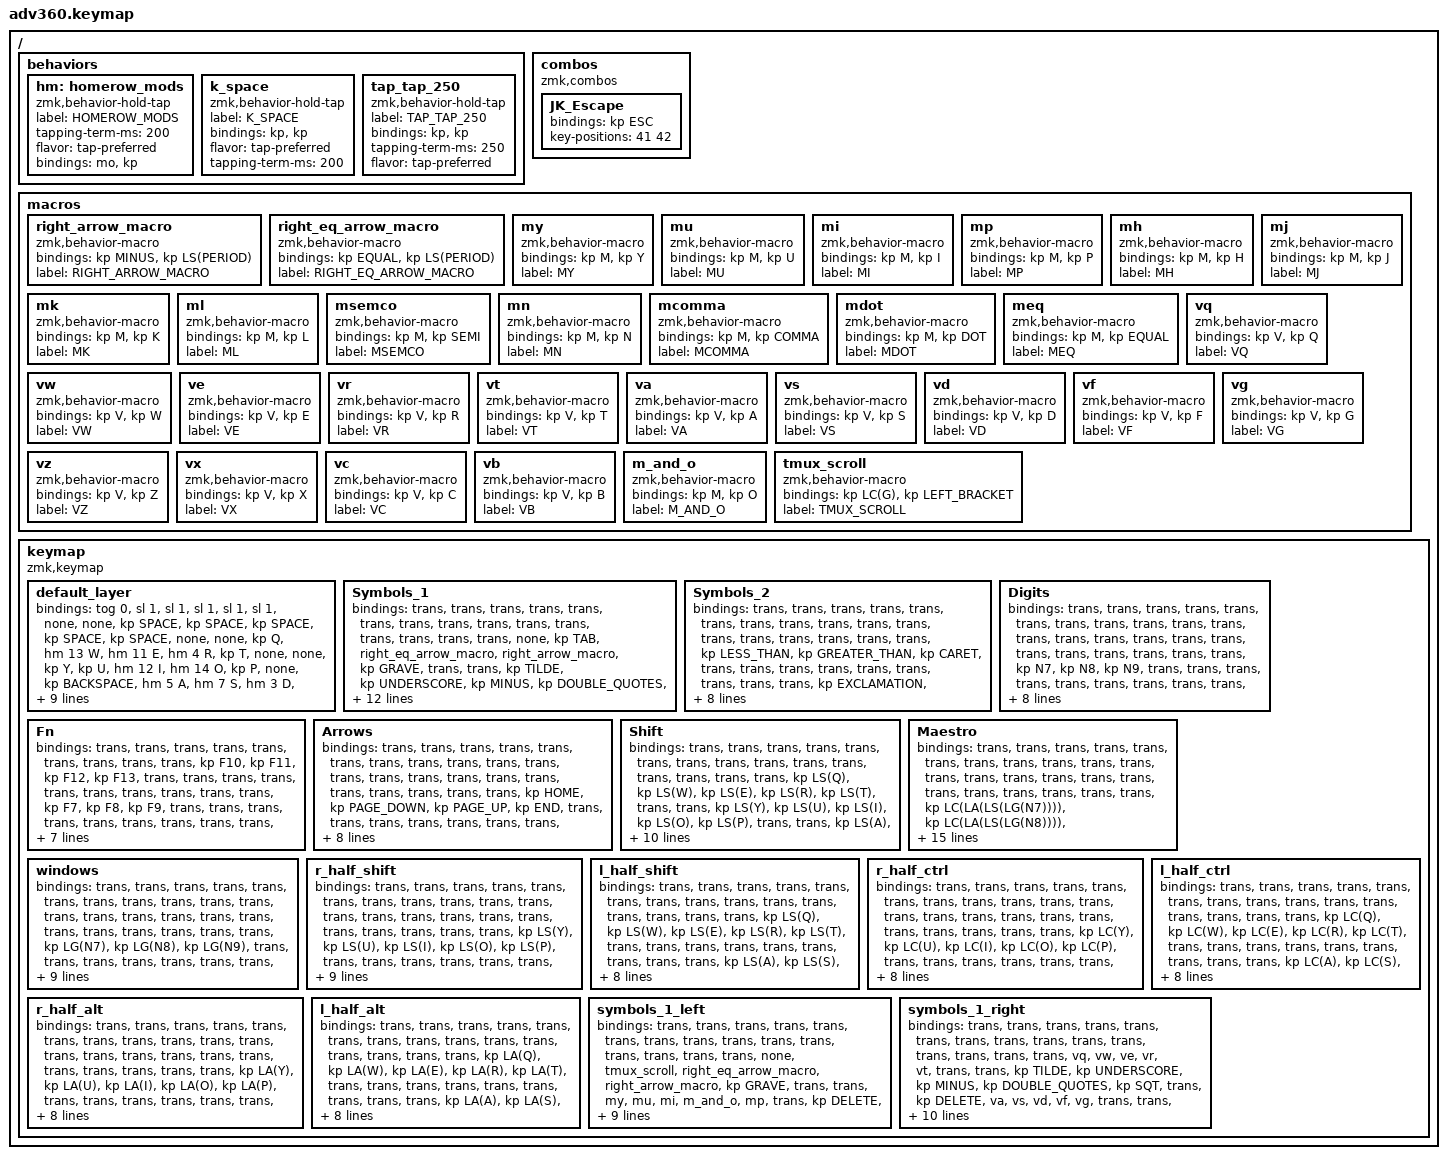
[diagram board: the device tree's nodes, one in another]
#include <behaviors.dtsi>
#include <dt-bindings/zmk/keys.h>

/ {
    behaviors {
        #include "macros.dtsi"
      #include "version.dtsi"
      #ifndef VERSION_MACRO



        #endif

        hm: homerow_mods {
            compatible = "zmk,behavior-hold-tap";
            label = "HOMEROW_MODS";
            #binding-cells = <2>;
            tapping-term-ms = <200>;
            flavor = "tap-preferred";
            bindings = <&mo>, <&kp>;
        };

        k_space: k_space {
            compatible = "zmk,behavior-hold-tap";
            label = "K_SPACE";
            bindings = <&kp>, <&kp>;

            #binding-cells = <2>;
            flavor = "tap-preferred";
            tapping-term-ms = <200>;
        };

        tap_tap_250: tap_tap_250 {
            compatible = "zmk,behavior-hold-tap";
            label = "TAP_TAP_250";
            bindings = <&kp>, <&kp>;

            #binding-cells = <2>;
            tapping-term-ms = <250>;
            flavor = "tap-preferred";
        };
    };

    combos {
        compatible = "zmk,combos";

        JK_Escape {
            bindings = <&kp ESC>;
            key-positions = <41 42>;
        };
    };

    macros {
        right_arrow_macro: right_arrow_macro {
            compatible = "zmk,behavior-macro";
            #binding-cells = <0>;
            bindings = <&kp MINUS &kp LS(PERIOD)>;
            label = "RIGHT_ARROW_MACRO";
        };

        right_eq_arrow_macro: right_eq_arrow_macro {
            compatible = "zmk,behavior-macro";
            #binding-cells = <0>;
            bindings = <&kp EQUAL &kp LS(PERIOD)>;
            label = "RIGHT_EQ_ARROW_MACRO";
        };

        my: my {
            compatible = "zmk,behavior-macro";
            #binding-cells = <0>;
            bindings = <&kp M &kp Y>;
            label = "MY";
        };

        mu: mu {
            compatible = "zmk,behavior-macro";
            #binding-cells = <0>;
            bindings = <&kp M &kp U>;
            label = "MU";
        };

        mi: mi {
            compatible = "zmk,behavior-macro";
            #binding-cells = <0>;
            bindings = <&kp M &kp I>;
            label = "MI";
        };

        mp: mp {
            compatible = "zmk,behavior-macro";
            #binding-cells = <0>;
            bindings = <&kp M &kp P>;
            label = "MP";
        };

        mh: mh {
            compatible = "zmk,behavior-macro";
            #binding-cells = <0>;
            bindings = <&kp M &kp H>;
            label = "MH";
        };

        mj: mj {
            compatible = "zmk,behavior-macro";
            #binding-cells = <0>;
            bindings = <&kp M &kp J>;
            label = "MJ";
        };

        mk: mk {
            compatible = "zmk,behavior-macro";
            #binding-cells = <0>;
            bindings = <&kp M &kp K>;
            label = "MK";
        };

        ml: ml {
            compatible = "zmk,behavior-macro";
            #binding-cells = <0>;
            bindings = <&kp M &kp L>;
            label = "ML";
        };

        msemco: msemco {
            compatible = "zmk,behavior-macro";
            #binding-cells = <0>;
            bindings = <&kp M &kp SEMI>;
            label = "MSEMCO";
        };

        mn: mn {
            compatible = "zmk,behavior-macro";
            #binding-cells = <0>;
            bindings = <&kp M &kp N>;
            label = "MN";
        };

        mcomma: mcomma {
            compatible = "zmk,behavior-macro";
            #binding-cells = <0>;
            bindings = <&kp M &kp COMMA>;
            label = "MCOMMA";
        };

        mdot: mdot {
            compatible = "zmk,behavior-macro";
            #binding-cells = <0>;
            bindings = <&kp M &kp DOT>;
            label = "MDOT";
        };

        meq: meq {
            compatible = "zmk,behavior-macro";
            #binding-cells = <0>;
            bindings = <&kp M &kp EQUAL>;
            label = "MEQ";
        };

        vq: vq {
            compatible = "zmk,behavior-macro";
            #binding-cells = <0>;
            bindings = <&kp V &kp Q>;
            label = "VQ";
        };

        vw: vw {
            compatible = "zmk,behavior-macro";
            #binding-cells = <0>;
            bindings = <&kp V &kp W>;
            label = "VW";
        };

        ve: ve {
            compatible = "zmk,behavior-macro";
            #binding-cells = <0>;
            bindings = <&kp V &kp E>;
            label = "VE";
        };

        vr: vr {
            compatible = "zmk,behavior-macro";
            #binding-cells = <0>;
            bindings = <&kp V &kp R>;
            label = "VR";
        };

        vt: vt {
            compatible = "zmk,behavior-macro";
            #binding-cells = <0>;
            bindings = <&kp V &kp T>;
            label = "VT";
        };

        va: va {
            compatible = "zmk,behavior-macro";
            #binding-cells = <0>;
            bindings = <&kp V &kp A>;
            label = "VA";
        };

        vs: vs {
            compatible = "zmk,behavior-macro";
            #binding-cells = <0>;
            bindings = <&kp V &kp S>;
            label = "VS";
        };

        vd: vd {
            compatible = "zmk,behavior-macro";
            #binding-cells = <0>;
            bindings = <&kp V &kp D>;
            label = "VD";
        };

        vf: vf {
            compatible = "zmk,behavior-macro";
            #binding-cells = <0>;
            bindings = <&kp V &kp F>;
            label = "VF";
        };

        vg: vg {
            compatible = "zmk,behavior-macro";
            #binding-cells = <0>;
            bindings = <&kp V &kp G>;
            label = "VG";
        };

        vz: vz {
            compatible = "zmk,behavior-macro";
            #binding-cells = <0>;
            bindings = <&kp V &kp Z>;
            label = "VZ";
        };

        vx: vx {
            compatible = "zmk,behavior-macro";
            #binding-cells = <0>;
            bindings = <&kp V &kp X>;
            label = "VX";
        };

        vc: vc {
            compatible = "zmk,behavior-macro";
            #binding-cells = <0>;
            bindings = <&kp V &kp C>;
            label = "VC";
        };

        vb: vb {
            compatible = "zmk,behavior-macro";
            #binding-cells = <0>;
            bindings = <&kp V &kp B>;
            label = "VB";
        };

        m_and_o: m_and_o {
            compatible = "zmk,behavior-macro";
            #binding-cells = <0>;
            bindings = <&kp M &kp O>;
            label = "M_AND_O";
        };

        tmux_scroll: tmux_scroll {
            compatible = "zmk,behavior-macro";
            #binding-cells = <0>;
            bindings = <&kp LC(G) &kp LEFT_BRACKET>;
            label = "TMUX_SCROLL";
        };
    };

    keymap {
        compatible = "zmk,keymap";

        default_layer {
            bindings = <
&tog 0         &sl 1    &sl 1     &sl 1     &sl 1     &sl 1  &none                                                        &none      &kp SPACE  &kp SPACE  &kp SPACE         &kp SPACE  &kp SPACE        &none
&none          &kp Q    &hm 13 W  &hm 11 E  &hm 4 R   &kp T  &none                                                        &none      &kp Y      &kp U      &hm 12 I          &hm 14 O   &kp P            &none
&kp BACKSPACE  &hm 5 A  &hm 7 S   &hm 3 D   &hm 9 F   &kp G  &none  &sl 1  &kp LEFT_COMMAND      &kp LGUI      &kp SPACE  &none      &kp H      &hm 10 J   &k_space K SPACE  &kp L      &hm 2 SEMICOLON  &kp ENTER
&none          &kp Z    &kp X     &hm 8 C   &hm 16 V  &kp B                &kp LEFT_GUI          &kp LEFT_GUI                        &kp N      &hm 15 M   &kp COMMA         &kp DOT    &kp EQUAL        &none
&none          &none    &none     &none     &none            &sl 1  &sl 6  &kp LEFT_GUI          &kp LEFT_GUI  &sl 6      &kp SPACE             &none      &none             &none      &none            &none
            >;
        };

        Symbols_1 {
            bindings = <
&trans      &trans  &trans     &trans                 &trans              &trans            &trans                                            &trans   &trans             &trans                &trans                 &trans             &trans           &trans
&trans      &none   &kp TAB    &right_eq_arrow_macro  &right_arrow_macro  &kp GRAVE         &trans                                            &trans   &kp TILDE          &kp UNDERSCORE        &kp MINUS              &kp DOUBLE_QUOTES  &kp SQT          &trans
&kp DELETE  &none   &kp LC(B)  &kp BACKSLASH          &kp SLASH           &kp LEFT_BRACKET  &trans  &trans  &trans      &trans  &kp TAB       &trans   &kp RIGHT_BRACKET  &kp LEFT_PARENTHESIS  &kp RIGHT_PARENTHESIS  &kp LEFT_BRACE     &kp RIGHT_BRACE  &trans
&trans      &trans  &trans     &kp LS(LC(C))          &kp LS(LC(V))       &trans                            &trans      &trans                         &trans             &kp AMPERSAND         &kp ASTERISK           &kp PIPE           &kp QUESTION     &trans
&trans      &trans  &trans     &trans                 &trans                                &trans  &none   &trans      &trans  &kp CAPSLOCK  &kp TAB                     &trans                &trans                 &trans             &trans           &trans
            >;
        };

        Symbols_2 {
            bindings = <
&trans  &trans           &trans       &trans         &trans            &trans       &trans                                      &trans  &trans  &trans  &trans  &trans  &trans  &trans
&trans  &trans           &trans       &kp LESS_THAN  &kp GREATER_THAN  &kp CARET    &trans                                      &trans  &trans  &trans  &trans  &trans  &trans  &trans
&trans  &kp EXCLAMATION  &kp AT_SIGN  &kp HASH       &kp DOLLAR        &kp PERCENT  &trans  &trans  &trans      &trans  &trans  &trans  &trans  &trans  &trans  &trans  &trans  &trans
&trans  &trans           &trans       &trans         &trans            &trans                       &trans      &trans                  &trans  &trans  &trans  &trans  &trans  &trans
&trans  &trans           &trans       &trans         &trans                         &trans  &trans  &trans      &trans  &trans  &trans          &trans  &trans  &trans  &trans  &trans
            >;
        };

        Digits {
            bindings = <
&trans  &trans  &trans  &trans  &trans  &trans  &trans                                      &trans  &trans  &trans        &trans        &trans        &trans  &trans
&trans  &trans  &trans  &trans  &trans  &trans  &trans                                      &trans  &trans  &kp N7        &kp N8        &kp N9        &trans  &trans
&trans  &trans  &trans  &trans  &trans  &trans  &trans  &trans  &trans      &trans  &trans  &trans  &kp N0  &kp NUMBER_4  &kp N5        &kp NUMBER_6  &trans  &trans
&trans  &trans  &trans  &trans  &trans  &trans                  &trans      &trans                  &trans  &kp NUMBER_1  &kp NUMBER_2  &kp NUMBER_3  &trans  &trans
&trans  &trans  &trans  &trans  &trans          &trans  &trans  &trans      &trans  &trans  &trans          &trans        &trans        &trans        &trans  &trans
            >;
        };

        Fn {
            bindings = <
&trans  &trans  &trans  &trans  &trans  &trans  &trans                                      &trans  &trans  &kp F10  &kp F11  &kp F12  &kp F13  &trans
&trans  &trans  &trans  &trans  &trans  &trans  &trans                                      &trans  &trans  &kp F7   &kp F8   &kp F9   &trans   &trans
&trans  &trans  &trans  &trans  &trans  &trans  &trans  &trans  &trans      &trans  &trans  &trans  &trans  &kp F4   &kp F5   &kp F6   &trans   &trans
&trans  &trans  &trans  &trans  &trans  &trans                  &trans      &trans                  &trans  &kp F1   &kp F2   &kp F3   &trans   &trans
&trans  &trans  &trans  &trans  &trans          &trans  &trans  &trans      &trans  &trans  &trans          &trans   &trans   &trans   &trans   &trans
            >;
        };

        Arrows {
            bindings = <
&trans  &trans  &trans  &trans  &trans  &trans  &trans                                      &trans  &trans    &trans          &trans        &trans     &trans  &trans
&trans  &trans  &trans  &trans  &trans  &trans  &trans                                      &trans  &kp HOME  &kp PAGE_DOWN   &kp PAGE_UP   &kp END    &trans  &trans
&trans  &trans  &trans  &trans  &trans  &trans  &trans  &trans  &trans      &trans  &trans  &trans  &kp LEFT  &kp DOWN_ARROW  &kp UP_ARROW  &kp RIGHT  &trans  &trans
&trans  &trans  &trans  &trans  &trans  &trans                  &trans      &trans                  &trans    &trans          &trans        &trans     &trans  &trans
&trans  &trans  &trans  &trans  &trans          &trans  &trans  &trans      &trans  &trans  &trans            &trans          &trans        &trans     &trans  &trans
            >;
        };

        Shift {
            bindings = <
&trans  &trans     &trans     &trans     &trans     &trans     &trans                                             &trans  &trans     &trans     &trans         &trans          &trans             &trans
&trans  &kp LS(Q)  &kp LS(W)  &kp LS(E)  &kp LS(R)  &kp LS(T)  &trans                                             &trans  &kp LS(Y)  &kp LS(U)  &kp LS(I)      &kp LS(O)       &kp LS(P)          &trans
&trans  &kp LS(A)  &kp LS(S)  &kp LS(D)  &kp LS(F)  &kp LS(G)  &trans  &trans  &trans      &trans  &trans         &trans  &kp LS(H)  &kp LS(J)  &kp LS(K)      &kp LS(L)       &kp LS(SEMICOLON)  &kp LS(ENTER)
&trans  &kp LS(Z)  &kp LS(X)  &kp LS(C)  &kp LS(V)  &kp LS(B)                  &trans      &trans                         &kp LS(N)  &kp LS(M)  &kp LS(COMMA)  &kp LS(PERIOD)  &kp LS(EQUAL)      &trans
&trans  &trans     &trans     &trans     &trans                &trans  &trans  &trans      &trans  &kp LS(ENTER)  &trans             &trans     &trans         &trans          &trans             &trans
            >;
        };

        Maestro {
            bindings = <
&trans  &trans  &trans  &trans  &trans  &trans  &trans                                      &trans  &trans                  &trans                        &trans                        &trans                        &trans  &trans
&trans  &trans  &trans  &trans  &trans  &trans  &trans                                      &trans  &trans                  &kp LC(LA(LS(LG(N7))))        &kp LC(LA(LS(LG(N8))))        &kp LC(LA(LS(LG(N9))))        &trans  &trans
&trans  &trans  &trans  &trans  &trans  &trans  &trans  &trans  &trans      &trans  &trans  &trans  &kp LC(LA(LS(LG(N0))))  &kp LC(LA(LS(LG(NUMBER_4))))  &kp LC(LA(LS(LG(N5))))        &kp LC(LA(LS(LG(NUMBER_6))))  &trans  &trans
&trans  &trans  &trans  &trans  &trans  &trans                  &trans      &trans                  &trans                  &kp LC(LA(LS(LG(NUMBER_1))))  &kp LC(LA(LS(LG(NUMBER_2))))  &kp LC(LA(LS(LG(NUMBER_3))))  &trans  &trans
&trans  &trans  &trans  &trans  &trans          &trans  &trans  &trans      &trans  &trans  &trans                          &trans                        &trans                        &trans                        &trans  &trans
            >;
        };

        windows {
            bindings = <
&trans  &trans  &trans  &trans  &trans  &trans  &trans                                      &trans  &trans      &trans            &trans            &trans            &trans  &trans
&trans  &trans  &trans  &trans  &trans  &trans  &trans                                      &trans  &trans      &kp LG(N7)        &kp LG(N8)        &kp LG(N9)        &trans  &trans
&trans  &trans  &trans  &trans  &trans  &trans  &trans  &trans  &trans      &trans  &trans  &trans  &kp LG(N0)  &kp LG(NUMBER_4)  &kp LG(N5)        &kp LG(NUMBER_6)  &trans  &trans
&trans  &trans  &trans  &trans  &trans  &trans                  &trans      &trans                  &trans      &kp LG(NUMBER_1)  &kp LG(NUMBER_2)  &kp LG(NUMBER_3)  &trans  &trans
&trans  &trans  &trans  &trans  &trans          &trans  &trans  &trans      &trans  &trans  &trans              &trans            &trans            &trans            &trans  &trans
            >;
        };

        r_half_shift {
            bindings = <
&trans  &trans  &trans  &trans  &trans  &trans  &trans                                      &trans  &trans     &trans     &trans         &trans          &trans             &trans
&trans  &trans  &trans  &trans  &trans  &trans  &trans                                      &trans  &kp LS(Y)  &kp LS(U)  &kp LS(I)      &kp LS(O)       &kp LS(P)          &trans
&trans  &trans  &trans  &trans  &trans  &trans  &trans  &trans  &trans      &trans  &trans  &trans  &kp LS(H)  &kp LS(J)  &kp LS(K)      &kp LS(L)       &kp LS(SEMICOLON)  &kp LS(ENTER)
&trans  &trans  &trans  &trans  &trans  &trans                  &trans      &trans                  &kp LS(N)  &kp LS(M)  &kp LS(COMMA)  &kp LS(PERIOD)  &kp LS(EQUAL)      &trans
&trans  &trans  &trans  &trans  &trans          &trans  &trans  &trans      &trans  &trans  &none              &trans     &trans         &trans          &trans             &trans
            >;
        };

        l_half_shift {
            bindings = <
&trans  &trans     &trans     &trans     &trans     &trans     &trans                                      &trans  &trans  &trans  &trans  &trans  &trans  &trans
&trans  &kp LS(Q)  &kp LS(W)  &kp LS(E)  &kp LS(R)  &kp LS(T)  &trans                                      &trans  &trans  &trans  &trans  &trans  &trans  &trans
&trans  &kp LS(A)  &kp LS(S)  &kp LS(D)  &kp LS(F)  &kp LS(G)  &trans  &trans  &trans      &trans  &trans  &trans  &trans  &trans  &trans  &trans  &trans  &trans
&trans  &kp LS(Z)  &kp LS(X)  &kp LS(C)  &kp LS(V)  &kp LS(B)                  &trans      &trans                  &trans  &trans  &trans  &trans  &trans  &trans
&trans  &trans     &trans     &trans     &trans                &trans  &trans  &trans      &trans  &trans  &trans          &trans  &trans  &trans  &trans  &trans
            >;
        };

        r_half_ctrl {
            bindings = <
&trans  &trans  &trans  &trans  &trans  &trans  &trans                                      &trans  &trans     &trans     &trans     &trans     &trans     &trans
&trans  &trans  &trans  &trans  &trans  &trans  &trans                                      &trans  &kp LC(Y)  &kp LC(U)  &kp LC(I)  &kp LC(O)  &kp LC(P)  &trans
&trans  &trans  &trans  &trans  &trans  &trans  &trans  &trans  &trans      &trans  &trans  &trans  &kp LC(H)  &kp LC(J)  &kp LC(K)  &kp LC(L)  &none      &none
&trans  &trans  &trans  &trans  &trans  &trans                  &trans      &trans                  &kp LC(N)  &kp LC(M)  &none      &none      &none      &trans
&trans  &trans  &trans  &trans  &trans          &trans  &trans  &trans      &trans  &trans  &trans             &trans     &trans     &trans     &trans     &trans
            >;
        };

        l_half_ctrl {
            bindings = <
&trans  &trans     &trans     &trans     &trans     &trans     &trans                                      &trans  &trans  &trans  &trans  &trans  &trans  &trans
&trans  &kp LC(Q)  &kp LC(W)  &kp LC(E)  &kp LC(R)  &kp LC(T)  &trans                                      &trans  &trans  &trans  &trans  &trans  &trans  &trans
&trans  &kp LC(A)  &kp LC(S)  &kp LC(D)  &kp LC(F)  &kp LC(G)  &trans  &trans  &trans      &trans  &trans  &trans  &trans  &trans  &trans  &trans  &trans  &trans
&trans  &kp LC(Z)  &kp LC(X)  &kp LC(C)  &kp LC(V)  &kp LC(B)                  &trans      &trans                  &trans  &trans  &trans  &trans  &trans  &trans
&trans  &trans     &trans     &trans     &trans                &trans  &trans  &trans      &trans  &trans  &trans          &trans  &trans  &trans  &trans  &trans
            >;
        };

        r_half_alt {
            bindings = <
&trans  &trans  &trans  &trans  &trans  &trans  &trans                                      &trans  &trans     &trans     &trans     &trans     &trans     &trans
&trans  &trans  &trans  &trans  &trans  &trans  &trans                                      &trans  &kp LA(Y)  &kp LA(U)  &kp LA(I)  &kp LA(O)  &kp LA(P)  &trans
&trans  &trans  &trans  &trans  &trans  &trans  &trans  &trans  &trans      &trans  &trans  &trans  &kp LA(H)  &kp LA(J)  &kp LA(K)  &kp LA(L)  &none      &none
&trans  &trans  &trans  &trans  &trans  &trans                  &trans      &trans                  &kp LA(N)  &kp LA(M)  &none      &none      &none      &trans
&trans  &trans  &trans  &trans  &trans          &trans  &trans  &trans      &trans  &none   &trans             &trans     &trans     &trans     &trans     &trans
            >;
        };

        l_half_alt {
            bindings = <
&trans  &trans     &trans     &trans     &trans     &trans     &trans                                      &trans  &trans  &trans  &trans  &trans  &trans  &trans
&trans  &kp LA(Q)  &kp LA(W)  &kp LA(E)  &kp LA(R)  &kp LA(T)  &trans                                      &trans  &trans  &trans  &trans  &trans  &trans  &trans
&trans  &kp LA(A)  &kp LA(S)  &kp LA(D)  &kp LA(F)  &kp LA(G)  &trans  &trans  &trans      &trans  &trans  &trans  &trans  &trans  &trans  &trans  &trans  &trans
&trans  &kp LA(Z)  &kp LA(X)  &kp LA(C)  &kp LA(V)  &kp LA(B)                  &trans      &trans                  &trans  &trans  &trans  &trans  &trans  &trans
&trans  &trans     &trans     &trans     &trans                &trans  &trans  &trans      &trans  &trans  &trans          &trans  &trans  &trans  &trans  &trans
            >;
        };

        symbols_1_left {
            bindings = <
&trans      &trans        &trans        &trans                 &trans              &trans            &trans                                            &trans   &trans  &trans  &trans   &trans    &trans   &trans
&trans      &none         &tmux_scroll  &right_eq_arrow_macro  &right_arrow_macro  &kp GRAVE         &trans                                            &trans   &my     &mu     &mi      &m_and_o  &mp      &trans
&kp DELETE  &tmux_scroll  &trans        &kp BACKSLASH          &kp SLASH           &kp LEFT_BRACKET  &trans  &trans  &trans      &trans  &kp TAB       &trans   &mh     &mj     &mk      &ml       &msemco  &trans
&trans      &trans        &trans        &kp LS(LC(C))          &kp LS(LC(V))       &trans                            &trans      &trans                         &mn     &none   &mcomma  &mdot     &meq     &trans
&trans      &trans        &trans        &trans                 &trans                                &trans  &none   &trans      &trans  &kp CAPSLOCK  &kp TAB          &trans  &trans   &trans    &trans   &trans
            >;
        };

        symbols_1_right {
            bindings = <
&trans      &trans  &trans  &trans  &trans  &trans  &trans                                            &trans   &trans             &trans                &trans                 &trans             &trans           &trans
&trans      &vq     &vw     &ve     &vr     &vt     &trans                                            &trans   &kp TILDE          &kp UNDERSCORE        &kp MINUS              &kp DOUBLE_QUOTES  &kp SQT          &trans
&kp DELETE  &va     &vs     &vd     &vf     &vg     &trans  &trans  &trans      &trans  &kp TAB       &trans   &kp RIGHT_BRACKET  &kp LEFT_PARENTHESIS  &kp RIGHT_PARENTHESIS  &kp LEFT_BRACE     &kp RIGHT_BRACE  &caps_word
&trans      &vz     &vx     &vc     &none   &vb                     &trans      &trans                         &kp TAB            &kp AMPERSAND         &kp ASTERISK           &kp PIPE           &kp QUESTION     &trans
&trans      &trans  &trans  &trans  &trans          &trans  &none   &trans      &trans  &kp CAPSLOCK  &kp TAB                     &trans                &trans                 &trans             &trans           &trans
            >;
        };
    };
};
